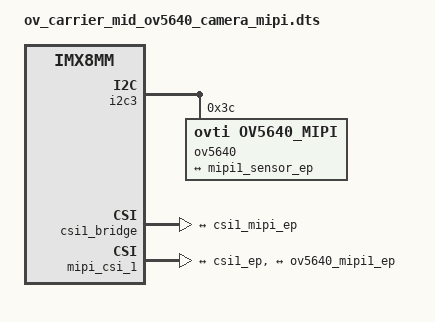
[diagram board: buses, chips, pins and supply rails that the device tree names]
/**
 * Portenta-X8 dtb overlay file
 * Arduino 2025
 * This overlay adds the Adafruit OV5640 Camera Module
 * based around cmos sensor Omnivision ov5640 to Portenta Mid carrier board
 */

/dts-v1/;
/plugin/;

#include <dt-bindings/gpio/gpio.h>
#include <dt-bindings/interrupt-controller/arm-gic.h>
#include <dt-bindings/clock/imx8mm-clock.h>
#include "imx8mm-pinfunc.h"

/ {
	compatible = "fsl,imx8mm-evk", "fsl,imx8mm";

	fragment@0 {
		target = <&i2c3>;
		__overlay__ {
			ov5640@3c {
				compatible = "ovti,ov5640_mipi";
				reg = <0x3c>;
				status = "okay";
				clocks = <&clk IMX8MM_CLK_CLKO1>;
				clock-names = "csi_mclk";
				assigned-clocks = <&clk IMX8MM_CLK_CLKO1>;
				assigned-clock-parents = <&clk IMX8MM_CLK_24M>;
				assigned-clock-rates = <24000000>;
				csi_id = <0>;
				//pwn-gpios = <&x8h7_gpio 4 GPIO_ACTIVE_HIGH>; /* stm32h7 PF12 */
				mclk = <24000000>;
				mclk_source = <0>;
				port {
					ov5640_mipi1_ep: endpoint {
						remote-endpoint = <&mipi1_sensor_ep>;
					};
				};
			};
		};
	};

	fragment@1 {
		target = <&csi1_bridge>;
		__overlay__ {
			fsl,mipi-mode;
			status = "okay";
			port {
				csi1_ep: endpoint {
					remote-endpoint = <&csi1_mipi_ep>;
				};
			};
		};
	};

	fragment@2 {
		target = <&mipi_csi_1>;
		__overlay__ {
			status = "okay";
			port {
				#address-cells = <1>;
				#size-cells = <0>;

				csi1_mipi_ep: endpoint@2 {
					reg = <2>;
					remote-endpoint = <&csi1_ep>;
				};

				mipi1_sensor_ep: endpoint@1 {
					reg = <1>;
					remote-endpoint = <&ov5640_mipi1_ep>;
					data-lanes = <2>;
					csis-hs-settle = <13>;
					csis-clk-settle = <2>;
					csis-wclk;
				};
			};
		};
	};
};
